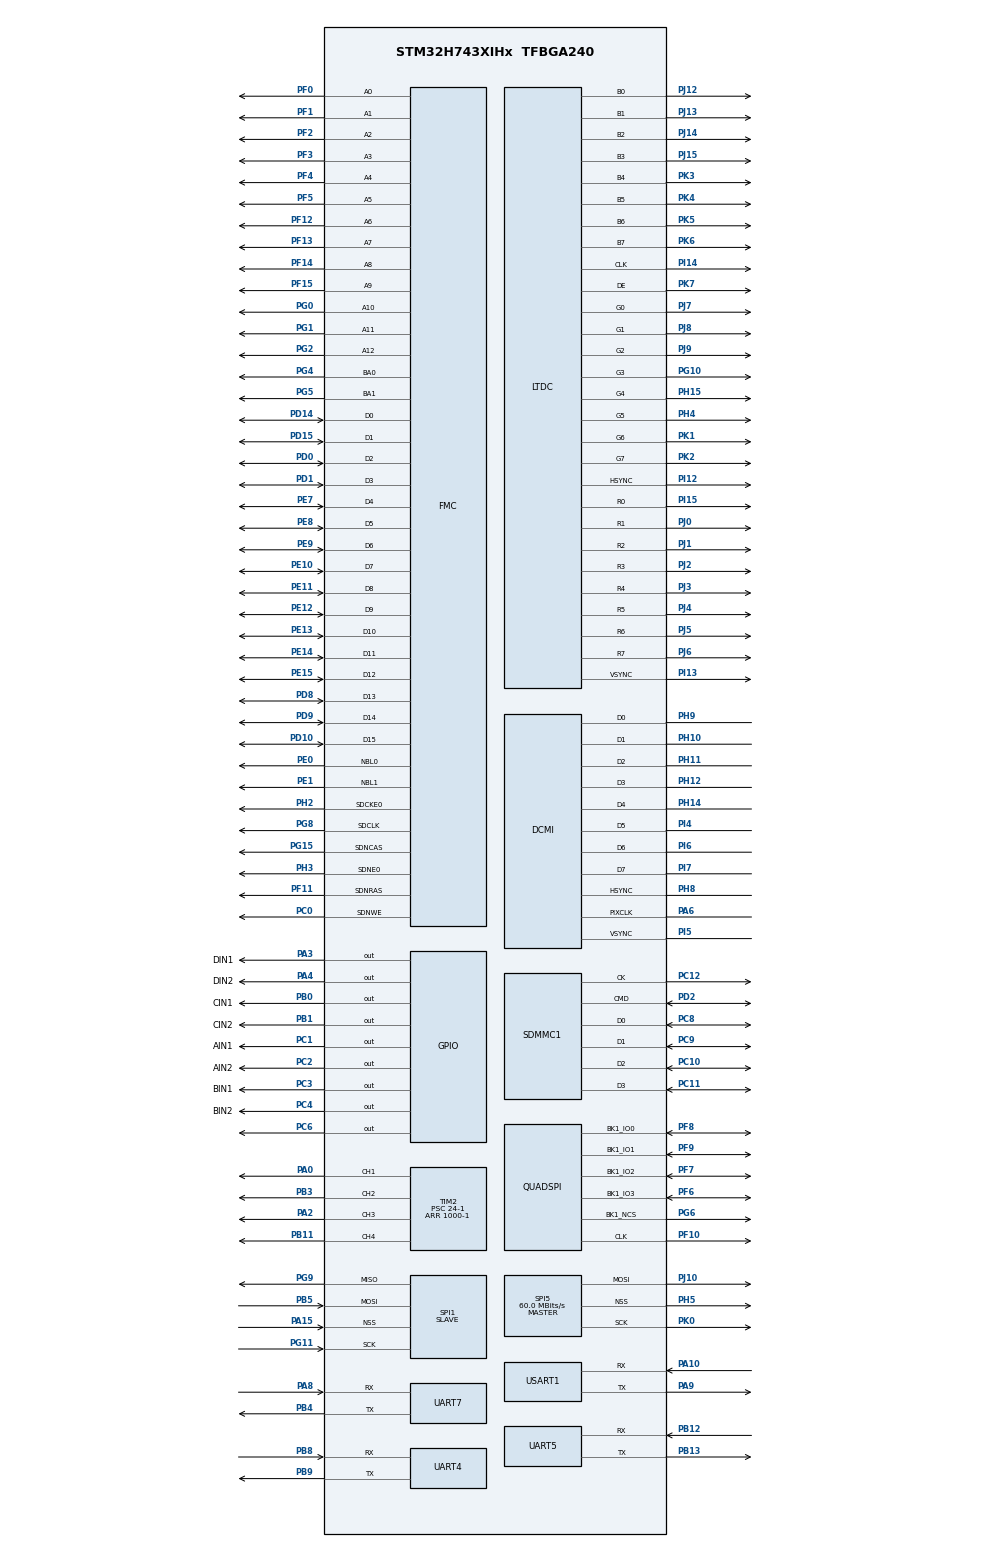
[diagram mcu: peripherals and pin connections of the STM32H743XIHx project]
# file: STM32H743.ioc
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CORTEX_M7.AccessPermission-Cortex_Memory_Protection_Unit_Region0_Settings=MPU_REGION_FULL_ACCESS
CORTEX_M7.AccessPermission-Cortex_Memory_Protection_Unit_Region1_Settings=MPU_REGION_FULL_ACCESS
CORTEX_M7.AccessPermission_Spec=MPU_REGION_FULL_ACCESS
CORTEX_M7.BaseAddress-Cortex_Memory_Protection_Unit_Region0_Settings=0xC0000000
CORTEX_M7.BaseAddress-Cortex_Memory_Protection_Unit_Region1_Settings=0x30000000
CORTEX_M7.BaseAddress_Spec=0xC0000000
CORTEX_M7.CPU_DCache=Enabled
CORTEX_M7.CPU_ICache=Enabled
CORTEX_M7.DisableExec_Spec=MPU_INSTRUCTION_ACCESS_ENABLE
CORTEX_M7.Enable-Cortex_Memory_Protection_Unit_Region0_Settings=MPU_REGION_ENABLE
CORTEX_M7.Enable-Cortex_Memory_Protection_Unit_Region1_Settings=MPU_REGION_ENABLE
CORTEX_M7.IsCacheable-Cortex_Memory_Protection_Unit_Region0_Settings=MPU_ACCESS_CACHEABLE
CORTEX_M7.IsCacheable_Spec=MPU_ACCESS_CACHEABLE
CORTEX_M7.IsShareable_Spec=MPU_ACCESS_NOT_SHAREABLE
CORTEX_M7.MPU_Control=MPU_HFNMI_PRIVDEF
CORTEX_M7.Size-Cortex_Memory_Protection_Unit_Region0_Settings=MPU_REGION_SIZE_32MB
CORTEX_M7.Size-Cortex_Memory_Protection_Unit_Region1_Settings=MPU_REGION_SIZE_512KB
CORTEX_M7.Size_Spec=MPU_REGION_SIZE_32MB
CORTEX_M7.SubRegionDisable_Spec=0x0
DMA2D.ColorMode=DMA2D_OUTPUT_RGB565
Dma.Request0=SPI1_RX
Dma.Request1=UART4_RX
Dma.SPI1_RX.0.Direction=DMA_PERIPH_TO_MEMORY
Dma.SPI1_RX.0.EventEnable=DISABLE
Dma.SPI1_RX.0.FIFOMode=DMA_FIFOMODE_DISABLE
Dma.SPI1_RX.0.Instance=DMA1_Stream0
Dma.SPI1_RX.0.MemDataAlignment=DMA_MDATAALIGN_BYTE
Dma.SPI1_RX.0.MemInc=DMA_MINC_ENABLE
Dma.SPI1_RX.0.Mode=DMA_CIRCULAR
Dma.SPI1_RX.0.PeriphDataAlignment=DMA_PDATAALIGN_BYTE
Dma.SPI1_RX.0.PeriphInc=DMA_PINC_DISABLE
Dma.SPI1_RX.0.Polarity=HAL_DMAMUX_REQ_GEN_RISING
Dma.SPI1_RX.0.Priority=DMA_PRIORITY_LOW
Dma.SPI1_RX.0.RequestNumber=1
Dma.SPI1_RX.0.SignalID=NONE
Dma.SPI1_RX.0.SyncEnable=DISABLE
Dma.SPI1_RX.0.SyncPolarity=HAL_DMAMUX_SYNC_NO_EVENT
Dma.SPI1_RX.0.SyncRequestNumber=1
Dma.SPI1_RX.0.SyncSignalID=NONE
Dma.UART4_RX.1.Direction=DMA_PERIPH_TO_MEMORY
Dma.UART4_RX.1.EventEnable=DISABLE
Dma.UART4_RX.1.FIFOMode=DMA_FIFOMODE_DISABLE
Dma.UART4_RX.1.Instance=DMA1_Stream1
Dma.UART4_RX.1.MemDataAlignment=DMA_MDATAALIGN_BYTE
Dma.UART4_RX.1.MemInc=DMA_MINC_ENABLE
Dma.UART4_RX.1.Mode=DMA_CIRCULAR
Dma.UART4_RX.1.PeriphDataAlignment=DMA_PDATAALIGN_BYTE
Dma.UART4_RX.1.PeriphInc=DMA_PINC_DISABLE
Dma.UART4_RX.1.Polarity=HAL_DMAMUX_REQ_GEN_RISING
Dma.UART4_RX.1.Priority=DMA_PRIORITY_LOW
Dma.UART4_RX.1.RequestNumber=1
Dma.UART4_RX.1.SignalID=NONE
Dma.UART4_RX.1.SyncEnable=DISABLE
Dma.UART4_RX.1.SyncPolarity=HAL_DMAMUX_SYNC_NO_EVENT
Dma.UART4_RX.1.SyncRequestNumber=1
Dma.UART4_RX.1.SyncSignalID=NONE
FMC.CASLatency1=FMC_SDRAM_CAS_LATENCY_3
FMC.ColumnBitsNumber1=FMC_SDRAM_COLUMN_BITS_NUM_9
FMC.ExitSelfRefreshDelay1=7
FMC.LoadToActiveDelay1=2
FMC.RCDDelay1=2 
FMC.RPDelay1=2
FMC.ReadBurst1=FMC_SDRAM_RBURST_ENABLE
FMC.ReadPipeDelay1=FMC_SDRAM_RPIPE_DELAY_1
FMC.RowCycleDelay1=7
FMC.SDClockPeriod1=FMC_SDRAM_CLOCK_PERIOD_2
FMC.SelfRefreshTime1=4
FMC.WriteRecoveryTime1=3
FREERTOS.Tasks01=defaultTask,0,2048,StartDefaultTask,Default,NULL,Dynamic,NULL,NULL
FREERTOS.configUSE_TICK_HOOK=1
LTDC.ActiveW=800
LTDC.Alpha_L0=255
LTDC.FBStartAdress_L0=0xC0000000
LTDC.HBP=80
LTDC.HFP=200
LTDC.HSync=1
LTDC.ImageHeight_L0=480
LTDC.ImageWidth_L0=800
LTDC.Layers=0
LTDC.PixelFormat_L0=LTDC_PIXEL_FORMAT_RGB565
LTDC.VBP=20
LTDC.VFP=22
LTDC.VSync=1
LTDC.WindowX1_L0=800
LTDC.WindowY1_L0=480
Mcu.Family=STM32H7
Mcu.Name=STM32H743XIHx
Mcu.Package=TFBGA240
NVIC.DMA1_Stream0_IRQn=true\:5\:0\:false\:false\:true\:true\:false\:true\:true
NVIC.DMA1_Stream1_IRQn=true\:5\:0\:false\:false\:true\:true\:false\:true\:true
NVIC.PriorityGroup=NVIC_PRIORITYGROUP_4
NVIC.SPI1_IRQn=true\:5\:0\:false\:false\:true\:true\:false\:true\:true
NVIC.TIM1_UP_IRQn=true\:15\:0\:false\:false\:true\:false\:false\:true\:true
NVIC.TimeBase=TIM1_UP_IRQn
NVIC.TimeBaseIP=TIM1
NVIC.UART4_IRQn=true\:5\:0\:false\:false\:true\:true\:true\:true\:true
NVIC.UART5_IRQn=true\:5\:0\:false\:false\:true\:true\:true\:true\:true
NVIC.UART7_IRQn=true\:5\:0\:false\:false\:true\:true\:true\:true\:true
PA0.GPIO_Speed=GPIO_SPEED_FREQ_VERY_HIGH
PA0.Signal=S_TIM2_CH1_ETR
PA10.Mode=Asynchronous
PA10.Signal=USART1_RX
PA13\ (JTMS/SWDIO).Mode=Serial_Wire
PA13\ (JTMS/SWDIO).Signal=DEBUG_JTMS-SWDIO
PA14\ (JTCK/SWCLK).Mode=Serial_Wire
PA14\ (JTCK/SWCLK).Signal=DEBUG_JTCK-SWCLK
PA15\ (JTDI).GPIO_PuPd=GPIO_PULLUP
PA15\ (JTDI).GPIO_Speed=GPIO_SPEED_FREQ_VERY_HIGH
PA15\ (JTDI).Mode=NSS_Signal_Hard_Input
PA15\ (JTDI).Signal=SPI1_NSS
PA2.GPIO_Speed=GPIO_SPEED_FREQ_VERY_HIGH
PA2.Signal=S_TIM2_CH3
PA3.GPIO_Label=DIN1
PA3.GPIO_Speed=GPIO_SPEED_FREQ_VERY_HIGH
PA3.Signal=GPIO_Output
PA4.GPIO_Label=DIN2
PA4.GPIO_Speed=GPIO_SPEED_FREQ_VERY_HIGH
PA4.Signal=GPIO_Output
PA6.GPIO_Mode=GPIO_MODE_AF_PP
PA6.GPIO_PuPd=GPIO_NOPULL
PA6.GPIO_Speed=GPIO_SPEED_FREQ_VERY_HIGH
PA6.Mode=Slave_8_bits_External_Synchro
PA6.Signal=DCMI_PIXCLK
PA8.GPIO_Speed=GPIO_SPEED_FREQ_VERY_HIGH
PA8.Mode=Asynchronous
PA8.Signal=UART7_RX
PA9.Mode=Asynchronous
PA9.Signal=USART1_TX
PB0.GPIO_Label=CIN1
PB0.GPIO_Speed=GPIO_SPEED_FREQ_VERY_HIGH
PB0.Signal=GPIO_Output
PB1.GPIO_Label=CIN2
PB1.GPIO_Speed=GPIO_SPEED_FREQ_VERY_HIGH
PB1.Signal=GPIO_Output
PB11.GPIO_Speed=GPIO_SPEED_FREQ_VERY_HIGH
PB11.Signal=S_TIM2_CH4
PB12.GPIO_Speed=GPIO_SPEED_FREQ_VERY_HIGH
PB12.Mode=Asynchronous
PB12.Signal=UART5_RX
PB13.GPIO_Speed=GPIO_SPEED_FREQ_VERY_HIGH
PB13.Mode=Asynchronous
PB13.Signal=UART5_TX
PB3\ (JTDO/TRACESWO).GPIO_Speed=GPIO_SPEED_FREQ_VERY_HIGH
PB3\ (JTDO/TRACESWO).Signal=S_TIM2_CH2
PB4\ (NJTRST).GPIO_Speed=GPIO_SPEED_FREQ_VERY_HIGH
PB4\ (NJTRST).Mode=Asynchronous
PB4\ (NJTRST).Signal=UART7_TX
PB5.GPIO_Speed=GPIO_SPEED_FREQ_VERY_HIGH
PB5.Mode=Full_Duplex_Slave
PB5.Signal=SPI1_MOSI
PB8.GPIO_FM8=SYSCFG_PMCR_I2C_PB8_FMP
PB8.GPIO_Speed=GPIO_SPEED_FREQ_VERY_HIGH
PB8.Mode=Asynchronous
PB8.Signal=UART4_RX
PB9.GPIO_FM9=SYSCFG_PMCR_I2C_PB9_FMP
PB9.GPIO_Speed=GPIO_SPEED_FREQ_VERY_HIGH
PB9.Mode=Asynchronous
PB9.Signal=UART4_TX
PC0.Signal=FMC_SDNWE
PC1.GPIO_Label=AIN1
PC1.GPIO_Speed=GPIO_SPEED_FREQ_VERY_HIGH
PC1.Signal=GPIO_Output
PC10.Mode=SD_4_bits_Wide_bus
PC10.Signal=SDMMC1_D2
PC11.Mode=SD_4_bits_Wide_bus
PC11.Signal=SDMMC1_D3
PC12.Mode=SD_4_bits_Wide_bus
PC12.Signal=SDMMC1_CK
PC14-OSC32_IN\ (OSC32_IN).Mode=LSE-External-Oscillator
PC14-OSC32_IN\ (OSC32_IN).Signal=RCC_OSC32_IN
PC15-OSC32_OUT\ (OSC32_OUT).Mode=LSE-External-Oscillator
PC15-OSC32_OUT\ (OSC32_OUT).Signal=RCC_OSC32_OUT
PC2.GPIO_Label=AIN2
PC2.GPIO_Speed=GPIO_SPEED_FREQ_VERY_HIGH
PC2.Signal=GPIO_Output
PC3.GPIO_Label=BIN1
PC3.GPIO_Speed=GPIO_SPEED_FREQ_VERY_HIGH
PC3.Signal=GPIO_Output
PC4.GPIO_Label=BIN2
PC4.GPIO_Speed=GPIO_SPEED_FREQ_VERY_HIGH
PC4.Signal=GPIO_Output
PC6.GPIO_PuPd=GPIO_PULLDOWN
PC6.GPIO_Speed=GPIO_SPEED_FREQ_VERY_HIGH
PC6.PinState=GPIO_PIN_SET
PC6.Signal=GPIO_Output
PC8.Mode=SD_4_bits_Wide_bus
PC8.Signal=SDMMC1_D0
PC9.Mode=SD_4_bits_Wide_bus
PC9.Signal=SDMMC1_D1
PD0.Signal=FMC_D2_DA2
PD1.Signal=FMC_D3_DA3
PD10.Signal=FMC_D15_DA15
PD14.Signal=FMC_D0_DA0
PD15.Signal=FMC_D1_DA1
PD2.Mode=SD_4_bits_Wide_bus
PD2.Signal=SDMMC1_CMD
PD8.Signal=FMC_D13_DA13
PD9.Signal=FMC_D14_DA14
PE0.Signal=FMC_NBL0
PE1.Signal=FMC_NBL1
PE10.Signal=FMC_D7_DA7
PE11.Signal=FMC_D8_DA8
PE12.Signal=FMC_D9_DA9
PE13.Signal=FMC_D10_DA10
PE14.Signal=FMC_D11_DA11
PE15.Signal=FMC_D12_DA12
PE7.Signal=FMC_D4_DA4
PE8.Signal=FMC_D5_DA5
PE9.Signal=FMC_D6_DA6
PF0.Signal=FMC_A0
PF1.Signal=FMC_A1
PF10.GPIO_Speed=GPIO_SPEED_FREQ_VERY_HIGH
PF10.Mode=Single Bank 1
PF10.Signal=QUADSPI_CLK
PF11.Signal=FMC_SDNRAS
PF12.Signal=FMC_A6
PF13.Signal=FMC_A7
PF14.Signal=FMC_A8
PF15.Signal=FMC_A9
PF2.Signal=FMC_A2
PF3.Signal=FMC_A3
PF4.Signal=FMC_A4
PF5.Signal=FMC_A5
PF6.GPIO_Speed=GPIO_SPEED_FREQ_VERY_HIGH
PF6.Mode=Single Bank 1
PF6.Signal=QUADSPI_BK1_IO3
PF7.GPIO_Speed=GPIO_SPEED_FREQ_VERY_HIGH
PF7.Mode=Single Bank 1
PF7.Signal=QUADSPI_BK1_IO2
PF8.GPIO_Speed=GPIO_SPEED_FREQ_VERY_HIGH
PF8.Mode=Single Bank 1
PF8.Signal=QUADSPI_BK1_IO0
PF9.GPIO_Speed=GPIO_SPEED_FREQ_VERY_HIGH
PF9.Mode=Single Bank 1
PF9.Signal=QUADSPI_BK1_IO1
PG0.Signal=FMC_A10
PG1.Signal=FMC_A11
PG10.Mode=RGB888
PG10.Signal=LTDC_G3
PG11.GPIO_Speed=GPIO_SPEED_FREQ_VERY_HIGH
PG11.Mode=Full_Duplex_Slave
PG11.Signal=SPI1_SCK
PG15.Signal=FMC_SDNCAS
PG2.Signal=FMC_A12
PG4.Signal=FMC_A14_BA0
PG5.Signal=FMC_A15_BA1
PG6.GPIO_Speed=GPIO_SPEED_FREQ_VERY_HIGH
PG6.Mode=Single Bank 1
PG6.Signal=QUADSPI_BK1_NCS
PG8.Signal=FMC_SDCLK
PG9.GPIO_Speed=GPIO_SPEED_FREQ_VERY_HIGH
PG9.Mode=Full_Duplex_Slave
PG9.Signal=SPI1_MISO
PH0-OSC_IN\ (PH0).Mode=HSE-External-Oscillator
PH0-OSC_IN\ (PH0).Signal=RCC_OSC_IN
PH1-OSC_OUT\ (PH1).Mode=HSE-External-Oscillator
PH1-OSC_OUT\ (PH1).Signal=RCC_OSC_OUT
PH10.GPIO_Mode=GPIO_MODE_AF_PP
PH10.GPIO_PuPd=GPIO_NOPULL
PH10.GPIO_Speed=GPIO_SPEED_FREQ_VERY_HIGH
PH10.Mode=Slave_8_bits_External_Synchro
PH10.Signal=DCMI_D1
PH11.GPIO_Mode=GPIO_MODE_AF_PP
PH11.GPIO_PuPd=GPIO_NOPULL
PH11.GPIO_Speed=GPIO_SPEED_FREQ_VERY_HIGH
PH11.Mode=Slave_8_bits_External_Synchro
PH11.Signal=DCMI_D2
PH12.GPIO_Mode=GPIO_MODE_AF_PP
PH12.GPIO_PuPd=GPIO_NOPULL
PH12.GPIO_Speed=GPIO_SPEED_FREQ_VERY_HIGH
PH12.Mode=Slave_8_bits_External_Synchro
PH12.Signal=DCMI_D3
PH14.GPIO_Mode=GPIO_MODE_AF_PP
PH14.GPIO_PuPd=GPIO_NOPULL
PH14.GPIO_Speed=GPIO_SPEED_FREQ_VERY_HIGH
PH14.Mode=Slave_8_bits_External_Synchro
PH14.Signal=DCMI_D4
PH15.Mode=RGB888
PH15.Signal=LTDC_G4
PH2.Mode=SdramChipSelect1_1
PH2.Signal=FMC_SDCKE0
PH3.Mode=SdramChipSelect1_1
PH3.Signal=FMC_SDNE0
PH4.Mode=RGB888
PH4.Signal=LTDC_G5
PH5.GPIO_Speed=GPIO_SPEED_FREQ_VERY_HIGH
PH5.Mode=NSS_Signal_Hard_Output
PH5.Signal=SPI5_NSS
PH8.GPIO_Mode=GPIO_MODE_AF_PP
PH8.GPIO_PuPd=GPIO_NOPULL
PH8.GPIO_Speed=GPIO_SPEED_FREQ_VERY_HIGH
PH8.Mode=Slave_8_bits_External_Synchro
PH8.Signal=DCMI_HSYNC
PH9.GPIO_Mode=GPIO_MODE_AF_PP
PH9.GPIO_PuPd=GPIO_NOPULL
PH9.GPIO_Speed=GPIO_SPEED_FREQ_VERY_HIGH
PH9.Mode=Slave_8_bits_External_Synchro
PH9.Signal=DCMI_D0
PI12.Mode=RGB888
PI12.Signal=LTDC_HSYNC
PI13.Mode=RGB888
PI13.Signal=LTDC_VSYNC
PI14.Mode=RGB888
PI14.Signal=LTDC_CLK
PI15.Mode=RGB888
PI15.Signal=LTDC_R0
PI4.GPIO_Mode=GPIO_MODE_AF_PP
PI4.GPIO_PuPd=GPIO_NOPULL
PI4.GPIO_Speed=GPIO_SPEED_FREQ_VERY_HIGH
PI4.Mode=Slave_8_bits_External_Synchro
PI4.Signal=DCMI_D5
PI5.GPIO_Mode=GPIO_MODE_AF_PP
PI5.GPIO_PuPd=GPIO_NOPULL
PI5.GPIO_Speed=GPIO_SPEED_FREQ_VERY_HIGH
PI5.Mode=Slave_8_bits_External_Synchro
PI5.Signal=DCMI_VSYNC
PI6.GPIO_Mode=GPIO_MODE_AF_PP
PI6.GPIO_PuPd=GPIO_NOPULL
PI6.GPIO_Speed=GPIO_SPEED_FREQ_VERY_HIGH
PI6.Mode=Slave_8_bits_External_Synchro
PI6.Signal=DCMI_D6
PI7.GPIO_Mode=GPIO_MODE_AF_PP
PI7.GPIO_PuPd=GPIO_NOPULL
PI7.GPIO_Speed=GPIO_SPEED_FREQ_VERY_HIGH
PI7.Mode=Slave_8_bits_External_Synchro
PI7.Signal=DCMI_D7
PJ0.Mode=RGB888
PJ0.Signal=LTDC_R1
PJ1.Mode=RGB888
PJ1.Signal=LTDC_R2
PJ10.GPIO_Speed=GPIO_SPEED_FREQ_VERY_HIGH
PJ10.Mode=TX_Only_Simplex_Unidirect_Master
PJ10.Signal=SPI5_MOSI
PJ12.Mode=RGB888
PJ12.Signal=LTDC_B0
PJ13.Mode=RGB888
PJ13.Signal=LTDC_B1
PJ14.Mode=RGB888
PJ14.Signal=LTDC_B2
PJ15.Mode=RGB888
PJ15.Signal=LTDC_B3
PJ2.Mode=RGB888
PJ2.Signal=LTDC_R3
PJ3.Mode=RGB888
PJ3.Signal=LTDC_R4
PJ4.Mode=RGB888
PJ4.Signal=LTDC_R5
PJ5.Mode=RGB888
PJ5.Signal=LTDC_R6
PJ6.Mode=RGB888
PJ6.Signal=LTDC_R7
PJ7.Mode=RGB888
PJ7.Signal=LTDC_G0
PJ8.Mode=RGB888
PJ8.Signal=LTDC_G1
PJ9.Mode=RGB888
PJ9.Signal=LTDC_G2
PK0.GPIO_Speed=GPIO_SPEED_FREQ_VERY_HIGH
PK0.Mode=TX_Only_Simplex_Unidirect_Master
PK0.Signal=SPI5_SCK
PK1.Mode=RGB888
PK1.Signal=LTDC_G6
PK2.Mode=RGB888
PK2.Signal=LTDC_G7
PK3.Mode=RGB888
PK3.Signal=LTDC_B4
PK4.Mode=RGB888
PK4.Signal=LTDC_B5
PK5.Mode=RGB888
PK5.Signal=LTDC_B6
PK6.Mode=RGB888
PK6.Signal=LTDC_B7
PK7.Mode=RGB888
PK7.Signal=LTDC_DE
ProjectManager.HeapSize=0x200
ProjectManager.StackSize=0x400
ProjectManager.TargetToolchain=CMake
QUADSPI.ClockMode=QSPI_CLOCK_MODE_3
QUADSPI.ClockPrescaler=1
QUADSPI.FifoThreshold=32
QUADSPI.FlashSize=22
QUADSPI.SampleShifting=QSPI_SAMPLE_SHIFTING_HALFCYCLE
RCC.ADCFreq_Value=200000000
RCC.APB1Freq_Value=120000000
RCC.APB2Freq_Value=120000000
RCC.APB3Freq_Value=120000000
RCC.APB4Freq_Value=120000000
RCC.CortexFreq_Value=480000000
RCC.D1PPRE=RCC_APB3_DIV2
RCC.D2PPRE1=RCC_APB1_DIV2
RCC.D2PPRE2=RCC_APB2_DIV2
RCC.D3PPRE=RCC_APB4_DIV2
RCC.DIVM1=5
RCC.DIVM2=8
RCC.DIVM3=25
RCC.DIVN1=192
RCC.DIVN2=128
RCC.DIVN3=330
RCC.DIVQ1=4
RCC.DIVR3=10
RCC.HCLKFreq_Value=240000000
RCC.HPRE=RCC_HCLK_DIV2
RCC.PLL2FRACN=0
RCC.PLL3FRACN=0
RCC.PLLFRACN=0
RCC.PLLSourceVirtual=RCC_PLLSOURCE_HSE
RCC.PWR_Regulator_Voltage_Scale=PWR_REGULATOR_VOLTAGE_SCALE0
RCC.ProductRev=revV
RCC.RTCClockSelection=RCC_RTCCLKSOURCE_LSE
RCC.SPI123CLockSelection=RCC_SPI123CLKSOURCE_PLL2
RCC.SYSCLKFreq_VALUE=480000000
RCC.SYSCLKSource=RCC_SYSCLKSOURCE_PLLCLK
RCC.USBFreq_Value=240000000
SDMMC1.ClockDiv=6
SH.FMC_A0.0=FMC_A0,13b-sda1
SH.FMC_A1.0=FMC_A1,13b-sda1
SH.FMC_A10.0=FMC_A10,13b-sda1
SH.FMC_A11.0=FMC_A11,13b-sda1
SH.FMC_A12.0=FMC_A12,13b-sda1
SH.FMC_A14_BA0.0=FMC_BA0,FourSdramBanks1
SH.FMC_A15_BA1.0=FMC_BA1,FourSdramBanks1
SH.FMC_A2.0=FMC_A2,13b-sda1
SH.FMC_A3.0=FMC_A3,13b-sda1
SH.FMC_A4.0=FMC_A4,13b-sda1
SH.FMC_A5.0=FMC_A5,13b-sda1
SH.FMC_A6.0=FMC_A6,13b-sda1
SH.FMC_A7.0=FMC_A7,13b-sda1
SH.FMC_A8.0=FMC_A8,13b-sda1
SH.FMC_A9.0=FMC_A9,13b-sda1
SH.FMC_D0_DA0.0=FMC_D0,sd-16b-d1
SH.FMC_D10_DA10.0=FMC_D10,sd-16b-d1
SH.FMC_D11_DA11.0=FMC_D11,sd-16b-d1
SH.FMC_D12_DA12.0=FMC_D12,sd-16b-d1
SH.FMC_D13_DA13.0=FMC_D13,sd-16b-d1
SH.FMC_D14_DA14.0=FMC_D14,sd-16b-d1
SH.FMC_D15_DA15.0=FMC_D15,sd-16b-d1
SH.FMC_D1_DA1.0=FMC_D1,sd-16b-d1
SH.FMC_D2_DA2.0=FMC_D2,sd-16b-d1
SH.FMC_D3_DA3.0=FMC_D3,sd-16b-d1
SH.FMC_D4_DA4.0=FMC_D4,sd-16b-d1
SH.FMC_D5_DA5.0=FMC_D5,sd-16b-d1
SH.FMC_D6_DA6.0=FMC_D6,sd-16b-d1
SH.FMC_D7_DA7.0=FMC_D7,sd-16b-d1
SH.FMC_D8_DA8.0=FMC_D8,sd-16b-d1
SH.FMC_D9_DA9.0=FMC_D9,sd-16b-d1
SH.FMC_NBL0.0=FMC_NBL0,Sd2ByteEnable1
SH.FMC_NBL1.0=FMC_NBL1,Sd2ByteEnable1
SH.FMC_SDCLK.0=FMC_SDCLK,13b-sda1
SH.FMC_SDNCAS.0=FMC_SDNCAS,13b-sda1
SH.FMC_SDNRAS.0=FMC_SDNRAS,13b-sda1
SH.FMC_SDNWE.0=FMC_SDNWE,13b-sda1
SH.S_TIM2_CH1_ETR.0=TIM2_CH1,PWM Generation1 CH1
SH.S_TIM2_CH2.0=TIM2_CH2,PWM Generation2 CH2
SH.S_TIM2_CH3.0=TIM2_CH3,PWM Generation3 CH3
SH.S_TIM2_CH4.0=TIM2_CH4,PWM Generation4 CH4
SPI1.CLKPhase=SPI_PHASE_2EDGE
SPI1.CLKPolarity=SPI_POLARITY_HIGH
SPI1.DataSize=SPI_DATASIZE_8BIT
SPI1.Direction=SPI_DIRECTION_2LINES
SPI1.Mode=SPI_MODE_SLAVE
SPI1.VirtualNSS=VM_NSSHARD
SPI1.VirtualType=VM_SLAVE
SPI5.CalculateBaudRate=60.0 MBits/s
SPI5.DataSize=SPI_DATASIZE_8BIT
SPI5.Direction=SPI_DIRECTION_2LINES_TXONLY
SPI5.FifoThreshold=SPI_FIFO_THRESHOLD_02DATA
SPI5.Mode=SPI_MODE_MASTER
SPI5.VirtualNSS=VM_NSSHARD
SPI5.VirtualType=VM_MASTER
TIM2.AutoReloadPreload=TIM_AUTORELOAD_PRELOAD_ENABLE
TIM2.Channel-PWM\ Generation1\ CH1=TIM_CHANNEL_1
TIM2.Channel-PWM\ Generation2\ CH2=TIM_CHANNEL_2
TIM2.Channel-PWM\ Generation3\ CH3=TIM_CHANNEL_3
TIM2.Channel-PWM\ Generation4\ CH4=TIM_CHANNEL_4
TIM2.Period=1000-1
TIM2.Prescaler=24-1
USART1.VirtualMode-Asynchronous=VM_ASYNC
VP_DMA2D_VS_DMA2D.Mode=DMA2D_Activate
VP_FREERTOS_VS_CMSIS_V1.Mode=CMSIS_V1
VP_RTC_VS_RTC_Activate.Mode=RTC_Enabled
VP_SYS_VS_tim1.Mode=TIM1
VP_TIM2_VS_ClockSourceINT.Mode=Internal
board=custom

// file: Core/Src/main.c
/* USER CODE BEGIN Header */
/**
  ******************************************************************************
  * @file           : main.c
  * @brief          : Main program body
  ******************************************************************************
  * @attention
  *
  * Copyright (c) 2026 STMicroelectronics.
  * All rights reserved.
  *
  * This software is licensed under terms that can be found in the LICENSE file
  * in the root directory of this software component.
  * If no LICENSE file comes with this software, it is provided AS-IS.
  *
  ******************************************************************************
  */
/* USER CODE END Header */
#include "main.h"
#include "cmsis_os.h"

/* USER CODE BEGIN Includes */
#include "mysys.h"
#include "led.h"
#include "motor.h"
#include "car_remote_ui.h"
#include "carcontrol.h"
#include "usart.h"
#include "sdram.h"
#include "lcd_rgb.h"
#include "touch_800x480.h"

#include "openmv_spi.h"
#include "openmv_uart.h"
#include "car_ball_pid.h"
#include "esp32_link.h"
#include "servo_uart5.h"
#include "ui.h"

#include "lcd_test.h"
#include <string.h>

#include "lvgl.h"
#include "lv_port_disp.h"
#include "lv_port_indev.h"
#include "others/sysmon/lv_sysmon.h"

/* USER CODE END Includes */

/* USER CODE BEGIN PD */
#define DEBUG_UART_LOG_ENABLE 0
/* USER CODE END PD */

DCMI_HandleTypeDef hdcmi;

DMA2D_HandleTypeDef hdma2d;

LTDC_HandleTypeDef hltdc;

QSPI_HandleTypeDef hqspi;

RTC_HandleTypeDef hrtc;

SD_HandleTypeDef hsd1;

SPI_HandleTypeDef hspi1;
SPI_HandleTypeDef hspi5;
DMA_HandleTypeDef hdma_spi1_rx;

TIM_HandleTypeDef htim2;

UART_HandleTypeDef huart4;
UART_HandleTypeDef huart5;
UART_HandleTypeDef huart7;
UART_HandleTypeDef huart1;
DMA_HandleTypeDef hdma_uart4_rx;

SDRAM_HandleTypeDef hsdram1;

osThreadId defaultTaskHandle;
/* USER CODE BEGIN PV */

osThreadId ledTaskHandle;
osThreadId fputTaskHandle;
osThreadId takeDataTaskHandle;
osThreadId processTaskHandle;
osThreadId servoTrackTaskHandle;

/* USER CODE END PV */

void SystemClock_Config(void);
static void MPU_Initialize(void);
static void MPU_Config(void);
static void MX_GPIO_Init(void);
static void MX_DMA_Init(void);
static void MX_RTC_Init(void);
static void MX_DCMI_Init(void);
static void MX_DMA2D_Init(void);
static void MX_FMC_Init(void);
static void MX_QUADSPI_Init(void);
static void MX_SDMMC1_SD_Init(void);
static void MX_SPI5_Init(void);
static void MX_USART1_UART_Init(void);
static void MX_LTDC_Init(void);
static void MX_SPI1_Init(void);
static void MX_UART4_Init(void);
static void MX_UART5_Init(void);
static void MX_TIM2_Init(void);
static void MX_UART7_Init(void);
void StartDefaultTask(void const * argument);

/* USER CODE BEGIN PFP */

void StartLedTask(void const * argument);
void StartFputTask(void const * argument);
void StartTakeDataTask(void const * argument);
void StartOpenmvProcessTask(void const * argument);
void StartServoTrackTask(void const * argument);
/* USER CODE END PFP */

/* USER CODE BEGIN 0 */

static uint8_t g_defer_ltdc_init = 1;
static uint8_t g_servo_task_enabled = 0;

/* USER CODE END 0 */

int main(void)
{

  /* Enable I-Cache---------------------------------------------------------*/
  SCB_EnableICache();

  /* Enable D-Cache---------------------------------------------------------*/
  SCB_EnableDCache();

  /* MCU Configuration--------------------------------------------------------*/

  /* Reset of all peripherals, Initializes the Flash interface and the Systick. */
  HAL_Init();

  /* MPU Configuration--------------------------------------------------------*/
  MPU_Config();

  /* Configure the system clock */
  SystemClock_Config();

  /* USER CODE BEGIN SysInit */
  mysysinit();
  /* USER CODE END SysInit */

  /* Initialize all configured peripherals */
  MX_GPIO_Init();
  MX_DMA_Init();
  MX_RTC_Init();
  MX_DCMI_Init();
  MX_DMA2D_Init();
  MX_FMC_Init();
  MX_QUADSPI_Init();
  MX_SDMMC1_SD_Init();
  MX_SPI5_Init();
  MX_USART1_UART_Init();
  MX_LTDC_Init();
  MX_SPI1_Init();
  MX_UART4_Init();
  MX_UART5_Init();
  MX_TIM2_Init();
  MX_UART7_Init();
  /* USER CODE BEGIN 2 */
  User_MX_FMC_Init();
  g_defer_ltdc_init = 0;
  MX_LTDC_Init();
  User_MX_LTDC_Init();
  User_USART1_Init();
  motor_init();
  car_init();
  servo_startup_self_test();
  LED_Init();
  Touch_Init();				// 触摸屏初始化

	lv_init();					//	LVGL��ʼ��
	lv_port_disp_init();		//	LVGL��ʾ�ӿڳ�ʼ��
	lv_port_indev_init();	// LVGL�����ӿڳ�ʼ��

  ui_init();
  lv_sysmon_show_performance(NULL);
  openmv_spi_init();

  /* USER CODE END 2 */

  /* Create the thread(s) */
  /* definition and creation of defaultTask */
  osThreadDef(defaultTask, StartDefaultTask, osPriorityNormal, 0, 2048);
  defaultTaskHandle = osThreadCreate(osThread(defaultTask), NULL);

  /* USER CODE BEGIN RTOS_THREADS */
  osThreadDef(ledTask, StartLedTask, osPriorityLow, 0, 128);
  ledTaskHandle = osThreadCreate(osThread(ledTask), NULL);
  /* add threads, ... */
  if (DEBUG_UART_LOG_ENABLE != 0)
  {
    osThreadDef(fputTask, StartFputTask, osPriorityLow, 0, 512);
    fputTaskHandle = osThreadCreate(osThread(fputTask), NULL);
  }
  else
  {
    fputTaskHandle = NULL;
  }

  /* 专门用于 OpenMV 数据处理的高优先级任务 */
  osThreadDef(takeDataTask, StartTakeDataTask, osPriorityHigh, 0, 384);
  takeDataTaskHandle = osThreadCreate(osThread(takeDataTask), NULL);

  /* 专门负责 SPI 图像处理的高优先级任务 */
  osThreadDef(processTask, StartOpenmvProcessTask, osPriorityNormal, 0, 384);
  processTaskHandle = osThreadCreate(osThread(processTask), NULL);

  osThreadDef(servoTrackTask, StartServoTrackTask, osPriorityHigh, 0, 256);
  servoTrackTaskHandle = osThreadCreate(osThread(servoTrackTask), NULL);
  if (servoTrackTaskHandle == NULL)
  {
    g_servo_task_enabled = 0;
  }
  else
  {
    g_servo_task_enabled = 1;
  }

  /* USER CODE END RTOS_THREADS */

  /* Start scheduler */
  osKernelStart();

  /* We should never get here as control is now taken by the scheduler */
  /* Infinite loop */
  while (1)
  {

  }
}

void SystemClock_Config(void)
{
  RCC_OscInitTypeDef RCC_OscInitStruct = {0};
  RCC_ClkInitTypeDef RCC_ClkInitStruct = {0};

  /** Supply configuration update enable
  */
  HAL_PWREx_ConfigSupply(PWR_LDO_SUPPLY);

  /** Configure the main internal regulator output voltage
  */
  __HAL_PWR_VOLTAGESCALING_CONFIG(PWR_REGULATOR_VOLTAGE_SCALE1);

  while(!__HAL_PWR_GET_FLAG(PWR_FLAG_VOSRDY)) {}

  __HAL_RCC_SYSCFG_CLK_ENABLE();
  __HAL_PWR_VOLTAGESCALING_CONFIG(PWR_REGULATOR_VOLTAGE_SCALE0);

  while(!__HAL_PWR_GET_FLAG(PWR_FLAG_VOSRDY)) {}

  /** Configure LSE Drive Capability
  */
  HAL_PWR_EnableBkUpAccess();
  __HAL_RCC_LSEDRIVE_CONFIG(RCC_LSEDRIVE_LOW);

  /** Initializes the RCC Oscillators according to the specified parameters
  * in the RCC_OscInitTypeDef structure.
  */
  RCC_OscInitStruct.OscillatorType = RCC_OSCILLATORTYPE_HSE|RCC_OSCILLATORTYPE_LSE;
  RCC_OscInitStruct.HSEState = RCC_HSE_ON;
  RCC_OscInitStruct.LSEState = RCC_LSE_ON;
  RCC_OscInitStruct.PLL.PLLState = RCC_PLL_ON;
  RCC_OscInitStruct.PLL.PLLSource = RCC_PLLSOURCE_HSE;
  RCC_OscInitStruct.PLL.PLLM = 5;
  RCC_OscInitStruct.PLL.PLLN = 192;
  RCC_OscInitStruct.PLL.PLLP = 2;
  RCC_OscInitStruct.PLL.PLLQ = 4;
  RCC_OscInitStruct.PLL.PLLR = 2;
  RCC_OscInitStruct.PLL.PLLRGE = RCC_PLL1VCIRANGE_2;
  RCC_OscInitStruct.PLL.PLLVCOSEL = RCC_PLL1VCOWIDE;
  RCC_OscInitStruct.PLL.PLLFRACN = 0;
  if (HAL_RCC_OscConfig(&RCC_OscInitStruct) != HAL_OK)
  {
    Error_Handler();
  }

  /** Initializes the CPU, AHB and APB buses clocks
  */
  RCC_ClkInitStruct.ClockType = RCC_CLOCKTYPE_HCLK|RCC_CLOCKTYPE_SYSCLK
                              |RCC_CLOCKTYPE_PCLK1|RCC_CLOCKTYPE_PCLK2
                              |RCC_CLOCKTYPE_D3PCLK1|RCC_CLOCKTYPE_D1PCLK1;
  RCC_ClkInitStruct.SYSCLKSource = RCC_SYSCLKSOURCE_PLLCLK;
  RCC_ClkInitStruct.SYSCLKDivider = RCC_SYSCLK_DIV1;
  RCC_ClkInitStruct.AHBCLKDivider = RCC_HCLK_DIV2;
  RCC_ClkInitStruct.APB3CLKDivider = RCC_APB3_DIV2;
  RCC_ClkInitStruct.APB1CLKDivider = RCC_APB1_DIV2;
  RCC_ClkInitStruct.APB2CLKDivider = RCC_APB2_DIV2;
  RCC_ClkInitStruct.APB4CLKDivider = RCC_APB4_DIV2;

  if (HAL_RCC_ClockConfig(&RCC_ClkInitStruct, FLASH_LATENCY_4) != HAL_OK)
  {
    Error_Handler();
  }
}

static void MX_DCMI_Init(void)
{

  hdcmi.Instance = DCMI;
  hdcmi.Init.SynchroMode = DCMI_SYNCHRO_HARDWARE;
  hdcmi.Init.PCKPolarity = DCMI_PCKPOLARITY_FALLING;
  hdcmi.Init.VSPolarity = DCMI_VSPOLARITY_LOW;
  hdcmi.Init.HSPolarity = DCMI_HSPOLARITY_LOW;
  hdcmi.Init.CaptureRate = DCMI_CR_ALL_FRAME;
  hdcmi.Init.ExtendedDataMode = DCMI_EXTEND_DATA_8B;
  hdcmi.Init.JPEGMode = DCMI_JPEG_DISABLE;
  hdcmi.Init.ByteSelectMode = DCMI_BSM_ALL;
  hdcmi.Init.ByteSelectStart = DCMI_OEBS_ODD;
  hdcmi.Init.LineSelectMode = DCMI_LSM_ALL;
  hdcmi.Init.LineSelectStart = DCMI_OELS_ODD;
  if (HAL_DCMI_Init(&hdcmi) != HAL_OK)
  {
    Error_Handler();
  }

}

static void MX_DMA2D_Init(void)
{

  hdma2d.Instance = DMA2D;
  hdma2d.Init.Mode = DMA2D_M2M;
  hdma2d.Init.ColorMode = DMA2D_OUTPUT_RGB565;
  hdma2d.Init.OutputOffset = 0;
  hdma2d.LayerCfg[1].InputOffset = 0;
  hdma2d.LayerCfg[1].InputColorMode = DMA2D_INPUT_RGB565;
  hdma2d.LayerCfg[1].AlphaMode = DMA2D_NO_MODIF_ALPHA;
  hdma2d.LayerCfg[1].InputAlpha = 0;
  hdma2d.LayerCfg[1].AlphaInverted = DMA2D_REGULAR_ALPHA;
  hdma2d.LayerCfg[1].RedBlueSwap = DMA2D_RB_REGULAR;
  hdma2d.LayerCfg[1].ChromaSubSampling = DMA2D_NO_CSS;
  if (HAL_DMA2D_Init(&hdma2d) != HAL_OK)
  {
    Error_Handler();
  }
  if (HAL_DMA2D_ConfigLayer(&hdma2d, 1) != HAL_OK)
  {
    Error_Handler();
  }

}

static void MX_LTDC_Init(void)
{

  /* USER CODE BEGIN LTDC_Init 0 */
  if (g_defer_ltdc_init != 0)
  {
    return;
  }

  /* USER CODE END LTDC_Init 0 */

  LTDC_LayerCfgTypeDef pLayerCfg = {0};

  hltdc.Instance = LTDC;
  hltdc.Init.HSPolarity = LTDC_HSPOLARITY_AL;
  hltdc.Init.VSPolarity = LTDC_VSPOLARITY_AL;
  hltdc.Init.DEPolarity = LTDC_DEPOLARITY_AL;
  hltdc.Init.PCPolarity = LTDC_PCPOLARITY_IPC;
  hltdc.Init.HorizontalSync = 0;
  hltdc.Init.VerticalSync = 0;
  hltdc.Init.AccumulatedHBP = 80;
  hltdc.Init.AccumulatedVBP = 20;
  hltdc.Init.AccumulatedActiveW = 880;
  hltdc.Init.AccumulatedActiveH = 500;
  hltdc.Init.TotalWidth = 1080;
  hltdc.Init.TotalHeigh = 522;
  hltdc.Init.Backcolor.Blue = 0;
  hltdc.Init.Backcolor.Green = 0;
  hltdc.Init.Backcolor.Red = 0;
  if (HAL_LTDC_Init(&hltdc) != HAL_OK)
  {
    Error_Handler();
  }
  pLayerCfg.WindowX0 = 0;
  pLayerCfg.WindowX1 = 800;
  pLayerCfg.WindowY0 = 0;
  pLayerCfg.WindowY1 = 480;
  pLayerCfg.PixelFormat = LTDC_PIXEL_FORMAT_RGB565;
  pLayerCfg.Alpha = 255;
  pLayerCfg.Alpha0 = 0;
  pLayerCfg.BlendingFactor1 = LTDC_BLENDING_FACTOR1_CA;
  pLayerCfg.BlendingFactor2 = LTDC_BLENDING_FACTOR2_CA;
  pLayerCfg.FBStartAdress = 0xC0000000;
  pLayerCfg.ImageWidth = 800;
  pLayerCfg.ImageHeight = 480;
  pLayerCfg.Backcolor.Blue = 0;
  pLayerCfg.Backcolor.Green = 0;
  pLayerCfg.Backcolor.Red = 0;
  if (HAL_LTDC_ConfigLayer(&hltdc, &pLayerCfg, 0) != HAL_OK)
  {
    Error_Handler();
  }

}

static void MX_QUADSPI_Init(void)
{

  /* QUADSPI parameter configuration*/
  hqspi.Instance = QUADSPI;
  hqspi.Init.ClockPrescaler = 1;
  hqspi.Init.FifoThreshold = 32;
  hqspi.Init.SampleShifting = QSPI_SAMPLE_SHIFTING_HALFCYCLE;
  hqspi.Init.FlashSize = 22;
  hqspi.Init.ChipSelectHighTime = QSPI_CS_HIGH_TIME_1_CYCLE;
  hqspi.Init.ClockMode = QSPI_CLOCK_MODE_3;
  hqspi.Init.FlashID = QSPI_FLASH_ID_1;
  hqspi.Init.DualFlash = QSPI_DUALFLASH_DISABLE;
  if (HAL_QSPI_Init(&hqspi) != HAL_OK)
  {
    Error_Handler();
  }

}

static void MX_RTC_Init(void)
{

  /** Initialize RTC Only
  */
  hrtc.Instance = RTC;
  hrtc.Init.HourFormat = RTC_HOURFORMAT_24;
  hrtc.Init.AsynchPrediv = 127;
  hrtc.Init.SynchPrediv = 255;
  hrtc.Init.OutPut = RTC_OUTPUT_DISABLE;
  hrtc.Init.OutPutPolarity = RTC_OUTPUT_POLARITY_HIGH;
  hrtc.Init.OutPutType = RTC_OUTPUT_TYPE_OPENDRAIN;
  hrtc.Init.OutPutRemap = RTC_OUTPUT_REMAP_NONE;
  if (HAL_RTC_Init(&hrtc) != HAL_OK)
  {
    Error_Handler();
  }

}

static void MX_SDMMC1_SD_Init(void)
{

  hsd1.Instance = SDMMC1;
  hsd1.Init.ClockEdge = SDMMC_CLOCK_EDGE_RISING;
  hsd1.Init.ClockPowerSave = SDMMC_CLOCK_POWER_SAVE_DISABLE;
  hsd1.Init.BusWide = SDMMC_BUS_WIDE_4B;
  hsd1.Init.HardwareFlowControl = SDMMC_HARDWARE_FLOW_CONTROL_DISABLE;
  hsd1.Init.ClockDiv = 6;
  if (HAL_SD_Init(&hsd1) != HAL_OK)
  {
    Error_Handler();
  }

}

static void MX_SPI1_Init(void)
{

  /* SPI1 parameter configuration*/
  hspi1.Instance = SPI1;
  hspi1.Init.Mode = SPI_MODE_SLAVE;
  hspi1.Init.Direction = SPI_DIRECTION_2LINES;
  hspi1.Init.DataSize = SPI_DATASIZE_8BIT;
  hspi1.Init.CLKPolarity = SPI_POLARITY_HIGH;
  hspi1.Init.CLKPhase = SPI_PHASE_2EDGE;
  hspi1.Init.NSS = SPI_NSS_HARD_INPUT;
  hspi1.Init.FirstBit = SPI_FIRSTBIT_MSB;
  hspi1.Init.TIMode = SPI_TIMODE_DISABLE;
  hspi1.Init.CRCCalculation = SPI_CRCCALCULATION_DISABLE;
  hspi1.Init.CRCPolynomial = 0x0;
  hspi1.Init.NSSPMode = SPI_NSS_PULSE_DISABLE;
  hspi1.Init.NSSPolarity = SPI_NSS_POLARITY_LOW;
  hspi1.Init.FifoThreshold = SPI_FIFO_THRESHOLD_01DATA;
  hspi1.Init.TxCRCInitializationPattern = SPI_CRC_INITIALIZATION_ALL_ZERO_PATTERN;
  hspi1.Init.RxCRCInitializationPattern = SPI_CRC_INITIALIZATION_ALL_ZERO_PATTERN;
  hspi1.Init.MasterSSIdleness = SPI_MASTER_SS_IDLENESS_00CYCLE;
  hspi1.Init.MasterInterDataIdleness = SPI_MASTER_INTERDATA_IDLENESS_00CYCLE;
  hspi1.Init.MasterReceiverAutoSusp = SPI_MASTER_RX_AUTOSUSP_DISABLE;
  hspi1.Init.MasterKeepIOState = SPI_MASTER_KEEP_IO_STATE_DISABLE;
  hspi1.Init.IOSwap = SPI_IO_SWAP_DISABLE;
  if (HAL_SPI_Init(&hspi1) != HAL_OK)
  {
    Error_Handler();
  }

}

static void MX_SPI5_Init(void)
{

  /* SPI5 parameter configuration*/
  hspi5.Instance = SPI5;
  hspi5.Init.Mode = SPI_MODE_MASTER;
  hspi5.Init.Direction = SPI_DIRECTION_2LINES_TXONLY;
  hspi5.Init.DataSize = SPI_DATASIZE_8BIT;
  hspi5.Init.CLKPolarity = SPI_POLARITY_LOW;
  hspi5.Init.CLKPhase = SPI_PHASE_1EDGE;
  hspi5.Init.NSS = SPI_NSS_HARD_OUTPUT;
  hspi5.Init.BaudRatePrescaler = SPI_BAUDRATEPRESCALER_2;
  hspi5.Init.FirstBit = SPI_FIRSTBIT_MSB;
  hspi5.Init.TIMode = SPI_TIMODE_DISABLE;
  hspi5.Init.CRCCalculation = SPI_CRCCALCULATION_DISABLE;
  hspi5.Init.CRCPolynomial = 0x0;
  hspi5.Init.NSSPMode = SPI_NSS_PULSE_ENABLE;
  hspi5.Init.NSSPolarity = SPI_NSS_POLARITY_LOW;
  hspi5.Init.FifoThreshold = SPI_FIFO_THRESHOLD_02DATA;
  hspi5.Init.TxCRCInitializationPattern = SPI_CRC_INITIALIZATION_ALL_ZERO_PATTERN;
  hspi5.Init.RxCRCInitializationPattern = SPI_CRC_INITIALIZATION_ALL_ZERO_PATTERN;
  hspi5.Init.MasterSSIdleness = SPI_MASTER_SS_IDLENESS_00CYCLE;
  hspi5.Init.MasterInterDataIdleness = SPI_MASTER_INTERDATA_IDLENESS_00CYCLE;
  hspi5.Init.MasterReceiverAutoSusp = SPI_MASTER_RX_AUTOSUSP_DISABLE;
  hspi5.Init.MasterKeepIOState = SPI_MASTER_KEEP_IO_STATE_DISABLE;
  hspi5.Init.IOSwap = SPI_IO_SWAP_DISABLE;
  if (HAL_SPI_Init(&hspi5) != HAL_OK)
  {
    Error_Handler();
  }

}

static void MX_TIM2_Init(void)
{

  TIM_ClockConfigTypeDef sClockSourceConfig = {0};
  TIM_MasterConfigTypeDef sMasterConfig = {0};
  TIM_OC_InitTypeDef sConfigOC = {0};

  htim2.Instance = TIM2;
  htim2.Init.Prescaler = 24-1;
  htim2.Init.CounterMode = TIM_COUNTERMODE_UP;
  htim2.Init.Period = 1000-1;
  htim2.Init.ClockDivision = TIM_CLOCKDIVISION_DIV1;
  htim2.Init.AutoReloadPreload = TIM_AUTORELOAD_PRELOAD_ENABLE;
  if (HAL_TIM_Base_Init(&htim2) != HAL_OK)
  {
    Error_Handler();
  }
  sClockSourceConfig.ClockSource = TIM_CLOCKSOURCE_INTERNAL;
  if (HAL_TIM_ConfigClockSource(&htim2, &sClockSourceConfig) != HAL_OK)
  {
    Error_Handler();
  }
  if (HAL_TIM_PWM_Init(&htim2) != HAL_OK)
  {
    Error_Handler();
  }
  sMasterConfig.MasterOutputTrigger = TIM_TRGO_RESET;
  sMasterConfig.MasterSlaveMode = TIM_MASTERSLAVEMODE_DISABLE;
  if (HAL_TIMEx_MasterConfigSynchronization(&htim2, &sMasterConfig) != HAL_OK)
  {
    Error_Handler();
  }
  sConfigOC.OCMode = TIM_OCMODE_PWM1;
  sConfigOC.Pulse = 0;
  sConfigOC.OCPolarity = TIM_OCPOLARITY_HIGH;
  sConfigOC.OCFastMode = TIM_OCFAST_DISABLE;
  if (HAL_TIM_PWM_ConfigChannel(&htim2, &sConfigOC, TIM_CHANNEL_1) != HAL_OK)
  {
    Error_Handler();
  }
  if (HAL_TIM_PWM_ConfigChannel(&htim2, &sConfigOC, TIM_CHANNEL_2) != HAL_OK)
  {
    Error_Handler();
  }
  if (HAL_TIM_PWM_ConfigChannel(&htim2, &sConfigOC, TIM_CHANNEL_3) != HAL_OK)
  {
    Error_Handler();
  }
  if (HAL_TIM_PWM_ConfigChannel(&htim2, &sConfigOC, TIM_CHANNEL_4) != HAL_OK)
  {
    Error_Handler();
  }
  HAL_TIM_MspPostInit(&htim2);

}

static void MX_UART4_Init(void)
{

  huart4.Instance = UART4;
  huart4.Init.BaudRate = 115200;
  huart4.Init.WordLength = UART_WORDLENGTH_8B;
  huart4.Init.StopBits = UART_STOPBITS_1;
  huart4.Init.Parity = UART_PARITY_NONE;
  huart4.Init.Mode = UART_MODE_TX_RX;
  huart4.Init.HwFlowCtl = UART_HWCONTROL_NONE;
  huart4.Init.OverSampling = UART_OVERSAMPLING_16;
  huart4.Init.OneBitSampling = UART_ONE_BIT_SAMPLE_DISABLE;
  huart4.Init.ClockPrescaler = UART_PRESCALER_DIV1;
  huart4.AdvancedInit.AdvFeatureInit = UART_ADVFEATURE_NO_INIT;
  if (HAL_UART_Init(&huart4) != HAL_OK)
  {
    Error_Handler();
  }
  if (HAL_UARTEx_SetTxFifoThreshold(&huart4, UART_TXFIFO_THRESHOLD_1_8) != HAL_OK)
  {
    Error_Handler();
  }
  if (HAL_UARTEx_SetRxFifoThreshold(&huart4, UART_RXFIFO_THRESHOLD_1_8) != HAL_OK)
  {
    Error_Handler();
  }
  if (HAL_UARTEx_DisableFifoMode(&huart4) != HAL_OK)
  {
    Error_Handler();
  }

}

static void MX_UART5_Init(void)
{

  huart5.Instance = UART5;
  huart5.Init.BaudRate = 115200;
  huart5.Init.WordLength = UART_WORDLENGTH_8B;
  huart5.Init.StopBits = UART_STOPBITS_1;
  huart5.Init.Parity = UART_PARITY_NONE;
  huart5.Init.Mode = UART_MODE_TX_RX;
  huart5.Init.HwFlowCtl = UART_HWCONTROL_NONE;
  huart5.Init.OverSampling = UART_OVERSAMPLING_16;
  huart5.Init.OneBitSampling = UART_ONE_BIT_SAMPLE_DISABLE;
  huart5.Init.ClockPrescaler = UART_PRESCALER_DIV1;
  huart5.AdvancedInit.AdvFeatureInit = UART_ADVFEATURE_NO_INIT;
  if (HAL_UART_Init(&huart5) != HAL_OK)
  {
    Error_Handler();
  }
  if (HAL_UARTEx_SetTxFifoThreshold(&huart5, UART_TXFIFO_THRESHOLD_1_8) != HAL_OK)
  {
    Error_Handler();
  }
  if (HAL_UARTEx_SetRxFifoThreshold(&huart5, UART_RXFIFO_THRESHOLD_1_8) != HAL_OK)
  {
    Error_Handler();
  }
  if (HAL_UARTEx_DisableFifoMode(&huart5) != HAL_OK)
  {
    Error_Handler();
  }

}

static void MX_UART7_Init(void)
{

  huart7.Instance = UART7;
  huart7.Init.BaudRate = 115200;
  huart7.Init.WordLength = UART_WORDLENGTH_8B;
  huart7.Init.StopBits = UART_STOPBITS_1;
  huart7.Init.Parity = UART_PARITY_NONE;
  huart7.Init.Mode = UART_MODE_TX_RX;
  huart7.Init.HwFlowCtl = UART_HWCONTROL_NONE;
  huart7.Init.OverSampling = UART_OVERSAMPLING_16;
  huart7.Init.OneBitSampling = UART_ONE_BIT_SAMPLE_DISABLE;
  huart7.Init.ClockPrescaler = UART_PRESCALER_DIV1;
  huart7.AdvancedInit.AdvFeatureInit = UART_ADVFEATURE_NO_INIT;
  if (HAL_UART_Init(&huart7) != HAL_OK)
  {
    Error_Handler();
  }
  if (HAL_UARTEx_SetTxFifoThreshold(&huart7, UART_TXFIFO_THRESHOLD_1_8) != HAL_OK)
  {
    Error_Handler();
  }
  if (HAL_UARTEx_SetRxFifoThreshold(&huart7, UART_RXFIFO_THRESHOLD_1_8) != HAL_OK)
  {
    Error_Handler();
  }
  if (HAL_UARTEx_DisableFifoMode(&huart7) != HAL_OK)
  {
    Error_Handler();
  }

}

static void MX_USART1_UART_Init(void)
{

  huart1.Instance = USART1;
  huart1.Init.BaudRate = 115200;
  huart1.Init.WordLength = UART_WORDLENGTH_8B;
  huart1.Init.StopBits = UART_STOPBITS_1;
  huart1.Init.Parity = UART_PARITY_NONE;
  huart1.Init.Mode = UART_MODE_TX_RX;
  huart1.Init.HwFlowCtl = UART_HWCONTROL_NONE;
  huart1.Init.OverSampling = UART_OVERSAMPLING_16;
  huart1.Init.OneBitSampling = UART_ONE_BIT_SAMPLE_DISABLE;
  huart1.Init.ClockPrescaler = UART_PRESCALER_DIV1;
  huart1.AdvancedInit.AdvFeatureInit = UART_ADVFEATURE_NO_INIT;
  if (HAL_UART_Init(&huart1) != HAL_OK)
  {
    Error_Handler();
  }
  if (HAL_UARTEx_SetTxFifoThreshold(&huart1, UART_TXFIFO_THRESHOLD_1_8) != HAL_OK)
  {
    Error_Handler();
  }
  if (HAL_UARTEx_SetRxFifoThreshold(&huart1, UART_RXFIFO_THRESHOLD_1_8) != HAL_OK)
  {
    Error_Handler();
  }
  if (HAL_UARTEx_DisableFifoMode(&huart1) != HAL_OK)
  {
    Error_Handler();
  }

}

static void MX_DMA_Init(void)
{

  /* DMA controller clock enable */
  __HAL_RCC_DMA1_CLK_ENABLE();

  /* DMA interrupt init */
  /* DMA1_Stream0_IRQn interrupt configuration */
  HAL_NVIC_SetPriority(DMA1_Stream0_IRQn, 5, 0);
  HAL_NVIC_EnableIRQ(DMA1_Stream0_IRQn);
  /* DMA1_Stream1_IRQn interrupt configuration */
  HAL_NVIC_SetPriority(DMA1_Stream1_IRQn, 5, 0);
  HAL_NVIC_EnableIRQ(DMA1_Stream1_IRQn);

}

/* FMC initialization function */
static void MX_FMC_Init(void)
{

  FMC_SDRAM_TimingTypeDef SdramTiming = {0};

  /** Perform the SDRAM1 memory initialization sequence
  */
  hsdram1.Instance = FMC_SDRAM_DEVICE;
  /* hsdram1.Init */
  hsdram1.Init.SDBank = FMC_SDRAM_BANK1;
  hsdram1.Init.ColumnBitsNumber = FMC_SDRAM_COLUMN_BITS_NUM_9;
  hsdram1.Init.RowBitsNumber = FMC_SDRAM_ROW_BITS_NUM_13;
  hsdram1.Init.MemoryDataWidth = FMC_SDRAM_MEM_BUS_WIDTH_16;
  hsdram1.Init.InternalBankNumber = FMC_SDRAM_INTERN_BANKS_NUM_4;
  hsdram1.Init.CASLatency = FMC_SDRAM_CAS_LATENCY_3;
  hsdram1.Init.WriteProtection = FMC_SDRAM_WRITE_PROTECTION_DISABLE;
  hsdram1.Init.SDClockPeriod = FMC_SDRAM_CLOCK_PERIOD_2;
  hsdram1.Init.ReadBurst = FMC_SDRAM_RBURST_ENABLE;
  hsdram1.Init.ReadPipeDelay = FMC_SDRAM_RPIPE_DELAY_1;
  /* SdramTiming */
  SdramTiming.LoadToActiveDelay = 2;
  SdramTiming.ExitSelfRefreshDelay = 7;
  SdramTiming.SelfRefreshTime = 4;
  SdramTiming.RowCycleDelay = 7;
  SdramTiming.WriteRecoveryTime = 3;
  SdramTiming.RPDelay = 2;
  SdramTiming.RCDDelay = 2 ;

  if (HAL_SDRAM_Init(&hsdram1, &SdramTiming) != HAL_OK)
  {
    Error_Handler( );
  }

}

static void MX_GPIO_Init(void)
{
  GPIO_InitTypeDef GPIO_InitStruct = {0};

  /* GPIO Ports Clock Enable */
  __HAL_RCC_GPIOI_CLK_ENABLE();
  __HAL_RCC_GPIOB_CLK_ENABLE();
  __HAL_RCC_GPIOK_CLK_ENABLE();
  __HAL_RCC_GPIOG_CLK_ENABLE();
  __HAL_RCC_GPIOC_CLK_ENABLE();
  __HAL_RCC_GPIOA_CLK_ENABLE();
  __HAL_RCC_GPIOE_CLK_ENABLE();
  __HAL_RCC_GPIOJ_CLK_ENABLE();
  __HAL_RCC_GPIOH_CLK_ENABLE();
  __HAL_RCC_GPIOD_CLK_ENABLE();
  __HAL_RCC_GPIOF_CLK_ENABLE();

  /*Configure GPIO pin Output Level */
  HAL_GPIO_WritePin(PICKUP_EN_GPIO_Port, PICKUP_EN_Pin, GPIO_PIN_RESET);

  /*Configure GPIO pin Output Level */
  HAL_GPIO_WritePin(GPIOC, AIN1_Pin|AIN2_Pin|BIN1_Pin|BIN2_Pin, GPIO_PIN_RESET);

  /*Configure GPIO pin Output Level */
  HAL_GPIO_WritePin(GPIOB, CIN2_Pin|CIN1_Pin, GPIO_PIN_RESET);

  /*Configure GPIO pin Output Level */
  HAL_GPIO_WritePin(GPIOA, DIN1_Pin|DIN2_Pin, GPIO_PIN_RESET);

  /*Configure GPIO pin : PC6 */
  GPIO_InitStruct.Pin = PICKUP_EN_Pin;
  GPIO_InitStruct.Mode = GPIO_MODE_OUTPUT_PP;
  GPIO_InitStruct.Pull = GPIO_PULLDOWN;
  GPIO_InitStruct.Speed = GPIO_SPEED_FREQ_VERY_HIGH;
  HAL_GPIO_Init(PICKUP_EN_GPIO_Port, &GPIO_InitStruct);

  /*Configure GPIO pins : AIN1_Pin AIN2_Pin BIN1_Pin BIN2_Pin */
  GPIO_InitStruct.Pin = AIN1_Pin|AIN2_Pin|BIN1_Pin|BIN2_Pin;
  GPIO_InitStruct.Mode = GPIO_MODE_OUTPUT_PP;
  GPIO_InitStruct.Pull = GPIO_NOPULL;
  GPIO_InitStruct.Speed = GPIO_SPEED_FREQ_VERY_HIGH;
  HAL_GPIO_Init(GPIOC, &GPIO_InitStruct);

  /*Configure GPIO pins : CIN2_Pin CIN1_Pin */
  GPIO_InitStruct.Pin = CIN2_Pin|CIN1_Pin;
  GPIO_InitStruct.Mode = GPIO_MODE_OUTPUT_PP;
  GPIO_InitStruct.Pull = GPIO_NOPULL;
  GPIO_InitStruct.Speed = GPIO_SPEED_FREQ_VERY_HIGH;
  HAL_GPIO_Init(GPIOB, &GPIO_InitStruct);

  /*Configure GPIO pins : DIN1_Pin DIN2_Pin */
  GPIO_InitStruct.Pin = DIN1_Pin|DIN2_Pin;
  GPIO_InitStruct.Mode = GPIO_MODE_OUTPUT_PP;
  GPIO_InitStruct.Pull = GPIO_NOPULL;
  GPIO_InitStruct.Speed = GPIO_SPEED_FREQ_VERY_HIGH;
  HAL_GPIO_Init(GPIOA, &GPIO_InitStruct);

}

/* USER CODE BEGIN 4 */
void StartLedTask(void const * argument)
{
    for(;;)
  {

		osDelay(500);
		LED1_Toggle;			// LED��˸
  }
}

/* 专门负责处理 OpenMV 数据的任务 (UART) */
void StartTakeDataTask(void const * argument)
{
    /* 初始化 UART4 DMA 接收 */
    openmv_uart_init();
    esp32_control_init();
    car_ball_pid_init();
    if (g_servo_task_enabled == 0)
    {
        servo_pid_init();
    }

    for(;;)
    {
        /* 处理 UART4 数据 */
        openmv_uart_process();
        esp32_control_process();
        if (esp32_control_get_mode() == ESP32_CONTROL_MODE_PICKUP)
        {
            if (g_servo_task_enabled == 0)
            {
                servo_pid_track_from_uart();
            }
            car_ball_pid_track_from_uart();
        }

        osDelay(1);
    }
}

void StartServoTrackTask(void const * argument)
{
    servo_pid_init();

    for(;;)
    {
        if (esp32_control_get_mode() == ESP32_CONTROL_MODE_PICKUP)
        {
            servo_pid_track_from_uart();
        }
        osDelay(5);
    }
}

/* 专门负责 SPI 图像处理的任务 */
void StartOpenmvProcessTask(void const * argument)
{
    for(;;)
    {
        /* 高频处理，确保双缓冲及时流转 */
        openmv_process();

        /* 检查超时：如果超过 500ms 没收到有效帧，就重启 SPI */
        openmv_check_timeout(500);

        osDelay(1);
    }
}

//fput任务（DMA接收测试输出）
void StartFputTask(void const * argument)
{
    openmv_meta_t openmv_data = {0};
    openmv_uart_data_t uart_data = {0};
    uint32_t last_spi_seq = 0;
    uint32_t last_uart_seq = 0;

    HAL_UART_Transmit(&huart1, (uint8_t *)"\r\n=== SPI & UART DATA MONITOR ===\r\n", 33, 100);

    for(;;)
    {
        /* 检查 SPI 或 UART 是否有新数据 */
        uint32_t curr_spi_seq = openmv_get_data_seq();
        uint32_t curr_uart_seq = openmv_uart_get_seq();

        if (curr_spi_seq != last_spi_seq || curr_uart_seq != last_uart_seq)
        {
            last_spi_seq = curr_spi_seq;
            last_uart_seq = curr_uart_seq;

            /* 获取最新数据 */
            openmv_get_meta(&openmv_data);
            openmv_uart_get_data(&uart_data);

            /* 打印合并后的状态 */
            printf("SPI_Seq:%lu UART_Seq:%lu | ROI(%d,%d) | Ball(%d,%d)\r\n",
                   (unsigned long)curr_spi_seq,
                   (unsigned long)curr_uart_seq,
                   openmv_data.roi_x,
                   openmv_data.roi_y,
                   uart_data.ball_x,
                   uart_data.ball_y);
        }
        else
        {
            /* 没收到数据时，打印调试信息 */
            /* 打印 UART4 ISR 寄存器，看看有没有 RXNE, ORE, FE 等标志 */
            /* ISR 寄存器定义因系列而异，H7 通常是 ISR */
            printf("Waiting... ISR=0x%08lX CNDTR=%lu\r\n",
                   huart4.Instance->ISR,
                   __HAL_DMA_GET_COUNTER(huart4.hdmarx));
        }
        osDelay(100); /* 降低打印频率 */
    }
}
/* USER CODE END 4 */

/* USER CODE BEGIN Header_StartDefaultTask */
/**
  * @brief  Function implementing the defaultTask thread.
  * @param  argument: Not used
  * @retval None
  */

  ///////////////////图像显示//////////////////////////////////////
/* OpenMV Canvas 相关变量 */
static lv_obj_t *openmv_canvas = NULL;
/* 静态分配 Canvas 缓冲区 (RGB565, 80x80) */
/* 使用 LV_CANVAS_BUF_SIZE 宏计算大小更严谨，但这里直接给足空间 */
static uint8_t canvas_buf[80 * 80 * 2];

void app_create_openmv_canvas(void)
{
    /* 创建 Canvas 对象，挂载到当前屏幕 */
    openmv_canvas = lv_canvas_create(lv_scr_act());

    /* 设置缓冲区 (80x80, RGB565) */
    lv_canvas_set_buffer(openmv_canvas, canvas_buf, 80, 80, LV_COLOR_FORMAT_RGB565);

    /* 居中显示 */
    lv_obj_center(openmv_canvas);

    /* 填充黑色背景 */
    lv_canvas_fill_bg(openmv_canvas, lv_color_hex(0x000000), LV_OPA_COVER);
}

void app_update_openmv_canvas(void)
{
    if (openmv_canvas == NULL) return;

    /* 获取最新的 OpenMV 图像数据 */
    uint8_t *img_ptr = openmv_get_image();

    if (img_ptr != NULL)
    {
        /* 拷贝图像数据到 Canvas 缓冲区 */
        /* 注意：这里假设 img_ptr 指向的数据也是 80x80 RGB565 */
        memcpy(canvas_buf, img_ptr, 80 * 80 * 2);

        /* 标记对象无效，触发重绘 */
        lv_obj_invalidate(openmv_canvas);
    }
}
////////////////////////////////////////////////////////////////////////////////////

/* USER CODE END Header_StartDefaultTask */
void StartDefaultTask(void const * argument)
{
  /* USER CODE BEGIN 5 */

  /* 初始化 Canvas */
  /* 确保在 ui_init 之后调用，此时 lv_scr_act() 才是有效的屏幕 */
  /* 如果 ui_init 在 StartDefaultTask 之前调用过，这里可以直接创建 */
  /* 为了安全，我们假设 ui_init 已经在 main() 里调过了，或者这里可以加个延时 */
  osDelay(100);
  car_remote_ui_init();
  app_create_openmv_canvas();

  /* Infinite loop */
  for(;;)
  {
    lv_task_handler();	// LVGL����
    Touch_Scan();			// ����ɨ�裬ɨ��Ƶ�ʲ��ܵ���10ms

    /* 刷新 OpenMV 图像 */
    app_update_openmv_canvas();

    osDelay(20);
  }
  /* USER CODE END 5 */
}

/* MPU Configuration */

void MPU_Config(void)
{
  MPU_Region_InitTypeDef MPU_InitStruct = {0};

  /* Disables the MPU */
  HAL_MPU_Disable();

  /** Initializes and configures the Region and the memory to be protected
  */
  MPU_InitStruct.Enable = MPU_REGION_ENABLE;
  MPU_InitStruct.Number = MPU_REGION_NUMBER0;
  MPU_InitStruct.BaseAddress = 0xC0000000;
  MPU_InitStruct.Size = MPU_REGION_SIZE_32MB;
  MPU_InitStruct.SubRegionDisable = 0x0;
  MPU_InitStruct.TypeExtField = MPU_TEX_LEVEL0;
  MPU_InitStruct.AccessPermission = MPU_REGION_FULL_ACCESS;
  MPU_InitStruct.DisableExec = MPU_INSTRUCTION_ACCESS_ENABLE;
  MPU_InitStruct.IsShareable = MPU_ACCESS_NOT_SHAREABLE;
  MPU_InitStruct.IsCacheable = MPU_ACCESS_CACHEABLE;
  MPU_InitStruct.IsBufferable = MPU_ACCESS_NOT_BUFFERABLE;

  HAL_MPU_ConfigRegion(&MPU_InitStruct);

  /** Initializes and configures the Region and the memory to be protected
  */
  MPU_InitStruct.Number = MPU_REGION_NUMBER1;
  MPU_InitStruct.BaseAddress = 0x30000000;
  MPU_InitStruct.Size = MPU_REGION_SIZE_512KB;
  MPU_InitStruct.IsCacheable = MPU_ACCESS_NOT_CACHEABLE;

  HAL_MPU_ConfigRegion(&MPU_InitStruct);
  /* Enables the MPU */
  HAL_MPU_Enable(MPU_HFNMI_PRIVDEF);

}

void HAL_TIM_PeriodElapsedCallback(TIM_HandleTypeDef *htim)
{
  if (htim->Instance == TIM1) {
    HAL_IncTick();
  }
}

void Error_Handler(void)
{
  __disable_irq();
  while (1)
  {
  }
}

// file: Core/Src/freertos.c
/* USER CODE BEGIN Header */
/**
  ******************************************************************************
  * File Name          : freertos.c
  * Description        : Code for freertos applications
  ******************************************************************************
  * @attention
  *
  * Copyright (c) 2026 STMicroelectronics.
  * All rights reserved.
  *
  * This software is licensed under terms that can be found in the LICENSE file
  * in the root directory of this software component.
  * If no LICENSE file comes with this software, it is provided AS-IS.
  *
  ******************************************************************************
  */
/* USER CODE END Header */

#include "FreeRTOS.h"
#include "task.h"
#include "main.h"

/* USER CODE BEGIN Includes */
#include "lvgl.h"
/* USER CODE END Includes */

/* GetIdleTaskMemory prototype (linked to static allocation support) */
void vApplicationGetIdleTaskMemory( StaticTask_t **ppxIdleTaskTCBBuffer, StackType_t **ppxIdleTaskStackBuffer, uint32_t *pulIdleTaskStackSize );

/* Hook prototypes */
void vApplicationTickHook(void);

/* USER CODE BEGIN 3 */
__weak void vApplicationTickHook( void )
{
   /* This function will be called by each tick interrupt if
   configUSE_TICK_HOOK is set to 1 in FreeRTOSConfig.h. User code can be
   added here, but the tick hook is called from an interrupt context, so
   code must not attempt to block, and only the interrupt safe FreeRTOS API
   functions can be used (those that end in FromISR()). */
   lv_tick_inc(1);
}
/* USER CODE END 3 */

/* USER CODE BEGIN GET_IDLE_TASK_MEMORY */
static StaticTask_t xIdleTaskTCBBuffer;
static StackType_t xIdleStack[configMINIMAL_STACK_SIZE];

void vApplicationGetIdleTaskMemory( StaticTask_t **ppxIdleTaskTCBBuffer, StackType_t **ppxIdleTaskStackBuffer, uint32_t *pulIdleTaskStackSize )
{
  *ppxIdleTaskTCBBuffer = &xIdleTaskTCBBuffer;
  *ppxIdleTaskStackBuffer = &xIdleStack[0];
  *pulIdleTaskStackSize = configMINIMAL_STACK_SIZE;
  /* place for user code */
}
/* USER CODE END GET_IDLE_TASK_MEMORY */
